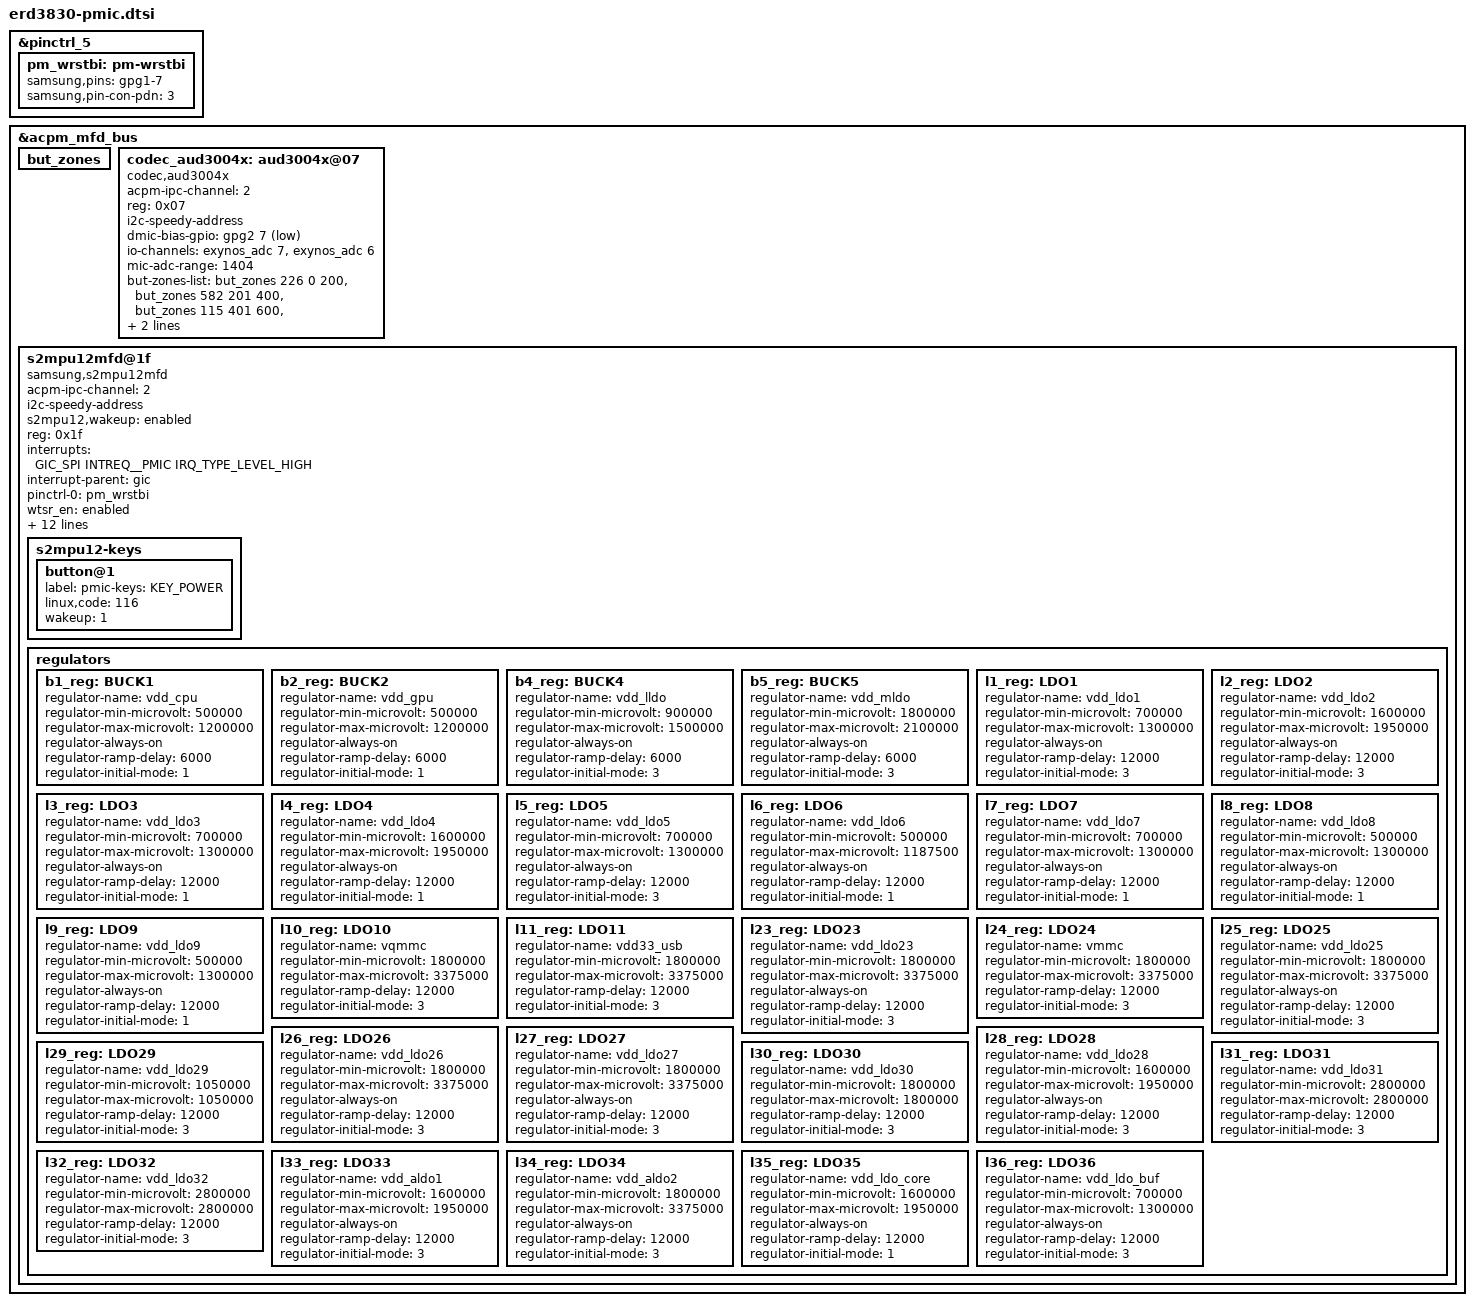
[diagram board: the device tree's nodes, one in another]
/*
 * SAMSUNG S5E3830 AP PMIC device tree source
 *
 * Copyright (c) 2022 Samsung Electronics Co., Ltd.
 *             http://www.samsung.com
 *
 * SAMSUNG S5E3830 AP PMIC device nodes are listed in this file.
 * AP PMIC based board files can include this file and provide
 * values for board specfic bindings.
 *
 * This program is free software; you can redistribute it and/or modify
 * it under the terms of the GNU General Public License version 2 as
 * published by the Free Software Foundation.
 */

&pinctrl_5 {
	pm_wrstbi: pm-wrstbi {
		samsung,pins = "gpg1-7";
		samsung,pin-con-pdn = <3>;
	};
};

&acpm_mfd_bus {
	status = "okay";
	#address-cells = <1>;
	#size-cells = <0>;

	but_zones: but_zones {
		#list-but-cells = <3>;
	};

	codec_aud3004x: aud3004x@07 {
		compatible = "codec,aud3004x";
		acpm-ipc-channel = <2>;
		#sound-dai-cells = <0>;
		reg = <0x07>;
		i2c-speedy-address;
		dmic-bias-gpio = <&gpg2 7 0xf>;
		pinctrl-names = "default";
		io-channels = <&exynos_adc 7>,<&exynos_adc 6>;
		io-channel-names = "adc-gdet","adc-ear";
		#io-channel-cells = <1>;
		mic-adc-range = <1404>;
		but-zones-list = <&but_zones 226 0 200>,
			<&but_zones 582 201 400>,
			<&but_zones 115 401 600>,
			<&but_zones 114 601 1161>;
		btn-release-value = <1404>;
	};

	s2mpu12mfd@1f {
		compatible = "samsung,s2mpu12mfd";
		acpm-ipc-channel = <2>;
		i2c-speedy-address;
		s2mpu12,wakeup = "enabled";
		reg = <0x1f>;
		interrupts = <GIC_SPI INTREQ__PMIC IRQ_TYPE_LEVEL_HIGH>;
		interrupt-parent = <&gic>;
		pinctrl-names = "default";
		pinctrl-0 = <&pm_wrstbi>;
		/* RTC: wtsr/smpl */
		wtsr_en = "enabled"; /* enable */
		smpl_en = "enabled"; /* enable */
		wtsr_timer_val = <3>;	/* 1000ms */
		smpl_timer_val = <4>;	/* 500ms */
		check_jigon = <0>; /* do not check jigon */
		/* RTC: If it's first boot, reset rtc to 1/1/2022 12:00:00(Sat) */
		init_time,sec = <0>;
		init_time,min = <0>;
		init_time,hour = <12>;
		init_time,mday = <1>;
		init_time,mon = <0>;
		init_time,year = <122>;
		init_time,wday = <6>;
		/* Loop BW */
		pmic_loop_bw;

		s2mpu12-keys {
			button@1 {
				label = "pmic-keys: KEY_POWER";
				linux,code = <116>;
				wakeup = <1>;
			};
		};

		regulators {
			b1_reg: BUCK1 {
				regulator-name = "vdd_cpu";
				regulator-min-microvolt = <500000>;
				regulator-max-microvolt = <1200000>;
				regulator-always-on;
				regulator-ramp-delay = <6000>;
				regulator-initial-mode = <1>;
			};

			b2_reg: BUCK2 {
				regulator-name = "vdd_gpu";
				regulator-min-microvolt = <500000>;
				regulator-max-microvolt = <1200000>;
				regulator-always-on;
				regulator-ramp-delay = <6000>;
				regulator-initial-mode = <1>;
			};
/*
			b3_reg: BUCK3 {
				regulator-name = "vdd_cp";
				regulator-min-microvolt = <500000>;
				regulator-max-microvolt = <1200000>;
				regulator-always-on;
				regulator-ramp-delay = <6000>;
				regulator-initial-mode = <3>;
			};
*/
			b4_reg: BUCK4 {
				regulator-name = "vdd_lldo";
				regulator-min-microvolt = <900000>;
				regulator-max-microvolt = <1500000>;
				regulator-always-on;
				regulator-ramp-delay = <6000>;
				regulator-initial-mode = <3>;
			};

			b5_reg: BUCK5 {
				regulator-name = "vdd_mldo";
				regulator-min-microvolt = <1800000>;
				regulator-max-microvolt = <2100000>;
				regulator-always-on;
				regulator-ramp-delay = <6000>;
				regulator-initial-mode = <3>;
			};

			l1_reg: LDO1 {
				regulator-name = "vdd_ldo1";
				regulator-min-microvolt = <700000>;
				regulator-max-microvolt = <1300000>;
				regulator-always-on;
				regulator-ramp-delay = <12000>;
				regulator-initial-mode = <3>;
			};

			l2_reg: LDO2 {
				regulator-name = "vdd_ldo2";
				regulator-min-microvolt = <1600000>;
				regulator-max-microvolt = <1950000>;
				regulator-always-on;
				regulator-ramp-delay = <12000>;
				regulator-initial-mode = <3>;
			};

			l3_reg: LDO3 {
				regulator-name = "vdd_ldo3";
				regulator-min-microvolt = <700000>;
				regulator-max-microvolt = <1300000>;
				regulator-always-on;
				regulator-ramp-delay = <12000>;
				regulator-initial-mode = <1>;
			};

			l4_reg: LDO4 {
				regulator-name = "vdd_ldo4";
				regulator-min-microvolt = <1600000>;
				regulator-max-microvolt = <1950000>;
				regulator-always-on;
				regulator-ramp-delay = <12000>;
				regulator-initial-mode = <1>;
			};

			l5_reg: LDO5 {
				regulator-name = "vdd_ldo5";
				regulator-min-microvolt = <700000>;
				regulator-max-microvolt = <1300000>;
				regulator-always-on;
				regulator-ramp-delay = <12000>;
				regulator-initial-mode = <3>;
			};

			l6_reg: LDO6 {
				regulator-name = "vdd_ldo6";
				regulator-min-microvolt = <500000>;
				regulator-max-microvolt = <1187500>;
				regulator-always-on;
				regulator-ramp-delay = <12000>;
				regulator-initial-mode = <1>;
			};

			l7_reg: LDO7 {
				regulator-name = "vdd_ldo7";
				regulator-min-microvolt = <700000>;
				regulator-max-microvolt = <1300000>;
				regulator-always-on;
				regulator-ramp-delay = <12000>;
				regulator-initial-mode = <1>;
			};

			l8_reg: LDO8 {
				regulator-name = "vdd_ldo8";
				regulator-min-microvolt = <500000>;
				regulator-max-microvolt = <1300000>;
				regulator-always-on;
				regulator-ramp-delay = <12000>;
				regulator-initial-mode = <1>;
			};

			l9_reg: LDO9 {
				regulator-name = "vdd_ldo9";
				regulator-min-microvolt = <500000>;
				regulator-max-microvolt = <1300000>;
				regulator-always-on;
				regulator-ramp-delay = <12000>;
				regulator-initial-mode = <1>;
			};

			l10_reg: LDO10 {
				regulator-name = "vqmmc";
				regulator-min-microvolt = <1800000>;
				regulator-max-microvolt = <3375000>;
				regulator-ramp-delay = <12000>;
				regulator-initial-mode = <3>;
			};

			l11_reg: LDO11 {
				regulator-name = "vdd33_usb";
				regulator-min-microvolt = <1800000>;
				regulator-max-microvolt = <3375000>;
				regulator-ramp-delay = <12000>;
				regulator-initial-mode = <3>;
			};
/*
			l12_reg: LDO12 {
				regulator-name = "vdd_ldo12";
				regulator-min-microvolt = <700000>;
				regulator-max-microvolt = <1300000>;
				regulator-always-on;
				regulator-ramp-delay = <12000>;
				regulator-initial-mode = <3>;
			};

			l13_reg: LDO13 {
				regulator-name = "vdd_ldo13";
				regulator-min-microvolt = <700000>;
				regulator-max-microvolt = <1300000>;
				regulator-always-on;
				regulator-ramp-delay = <12000>;
				regulator-initial-mode = <3>;
			};

			l14_reg: LDO14 {
				regulator-name = "vdd_ldo14";
				regulator-min-microvolt = <1600000>;
				regulator-max-microvolt = <1950000>;
				regulator-always-on;
				regulator-ramp-delay = <12000>;
				regulator-initial-mode = <3>;
			};

			l15_reg: LDO15 {
				regulator-name = "vdd_ldo15";
				regulator-min-microvolt = <1800000>;
				regulator-max-microvolt = <3375000>;
				regulator-always-on;
				regulator-ramp-delay = <12000>;
				regulator-initial-mode = <3>;
			};

			l16_reg: LDO16 {
				regulator-name = "vdd_ldo16";
				regulator-min-microvolt = <1800000>;
				regulator-max-microvolt = <3375000>;
				regulator-always-on;
				regulator-ramp-delay = <12000>;
				regulator-initial-mode = <3>;
			};

			l17_reg: LDO17 {
				regulator-name = "vdd_ldo17";
				regulator-min-microvolt = <700000>;
				regulator-max-microvolt = <1300000>;
				regulator-always-on;
				regulator-ramp-delay = <12000>;
				regulator-initial-mode = <3>;
			};

			l18_reg: LDO18 {
				regulator-name = "vdd_ldo18";
				regulator-min-microvolt = <700000>;
				regulator-max-microvolt = <1300000>;
				regulator-always-on;
				regulator-ramp-delay = <12000>;
				regulator-initial-mode = <3>;
			};

			l19_reg: LDO19 {
				regulator-name = "vdd_ldo19";
				regulator-min-microvolt = <700000>;
				regulator-max-microvolt = <1300000>;
				regulator-always-on;
				regulator-ramp-delay = <12000>;
				regulator-initial-mode = <3>;
			};

			l20_reg: LDO20 {
				regulator-name = "vdd_ldo20";
				regulator-min-microvolt = <1600000>;
				regulator-max-microvolt = <1950000>;
				regulator-always-on;
				regulator-ramp-delay = <12000>;
				regulator-initial-mode = <3>;
			};

			l21_reg: LDO21 {
				regulator-name = "vdd_ldo21";
				regulator-min-microvolt = <1800000>;
				regulator-max-microvolt = <3375000>;
				regulator-always-on;
				regulator-ramp-delay = <12000>;
				regulator-initial-mode = <3>;
			};

			l22_reg: LDO22 {
				regulator-name = "vdd_ldo22";
				regulator-min-microvolt = <1800000>;
				regulator-max-microvolt = <3375000>;
				regulator-always-on;
				regulator-ramp-delay = <12000>;
				regulator-initial-mode = <3>;
			};
*/
			l23_reg: LDO23 {
				regulator-name = "vdd_ldo23";
				regulator-min-microvolt = <1800000>;
				regulator-max-microvolt = <3375000>;
				regulator-always-on;
				regulator-ramp-delay = <12000>;
				regulator-initial-mode = <3>;
			};

			l24_reg: LDO24 {
				regulator-name = "vmmc";
				regulator-min-microvolt = <1800000>;
				regulator-max-microvolt = <3375000>;
				regulator-ramp-delay = <12000>;
				regulator-initial-mode = <3>;
			};

			l25_reg: LDO25 {
				regulator-name = "vdd_ldo25";
				regulator-min-microvolt = <1800000>;
				regulator-max-microvolt = <3375000>;
				regulator-always-on;
				regulator-ramp-delay = <12000>;
				regulator-initial-mode = <3>;
			};

			l26_reg: LDO26 {
				regulator-name = "vdd_ldo26";
				regulator-min-microvolt = <1800000>;
				regulator-max-microvolt = <3375000>;
				regulator-always-on;
				regulator-ramp-delay = <12000>;
				regulator-initial-mode = <3>;
			};

			l27_reg: LDO27 {
				regulator-name = "vdd_ldo27";
				regulator-min-microvolt = <1800000>;
				regulator-max-microvolt = <3375000>;
				regulator-always-on;
				regulator-ramp-delay = <12000>;
				regulator-initial-mode = <3>;
			};

			l28_reg: LDO28 {
				regulator-name = "vdd_ldo28";
				regulator-min-microvolt = <1600000>;
				regulator-max-microvolt = <1950000>;
				//regulator-boot-on;
				regulator-always-on;
				regulator-ramp-delay = <12000>;
				regulator-initial-mode = <3>;
			};

			l29_reg: LDO29 {
				regulator-name = "vdd_ldo29";
				regulator-min-microvolt = <1050000>;
				regulator-max-microvolt = <1050000>;
				regulator-ramp-delay = <12000>;
				regulator-initial-mode = <3>;
			};

			l30_reg: LDO30 {
				regulator-name = "vdd_ldo30";
				regulator-min-microvolt = <1800000>;
				regulator-max-microvolt = <1800000>;
				regulator-ramp-delay = <12000>;
				regulator-initial-mode = <3>;
			};

			l31_reg: LDO31 {
				regulator-name = "vdd_ldo31";
				regulator-min-microvolt = <2800000>;
				regulator-max-microvolt = <2800000>;
				regulator-ramp-delay = <12000>;
				regulator-initial-mode = <3>;
			};

			l32_reg: LDO32 {
				regulator-name = "vdd_ldo32";
				regulator-min-microvolt = <2800000>;
				regulator-max-microvolt = <2800000>;
				regulator-ramp-delay = <12000>;
				regulator-initial-mode = <3>;
			};

			l33_reg: LDO33 {
				regulator-name = "vdd_aldo1";
				regulator-min-microvolt = <1600000>;
				regulator-max-microvolt = <1950000>;
				regulator-always-on;
				regulator-ramp-delay = <12000>;
				regulator-initial-mode = <3>;
			};

			l34_reg: LDO34 {
				regulator-name = "vdd_aldo2";
				regulator-min-microvolt = <1800000>;
				regulator-max-microvolt = <3375000>;
				regulator-always-on;
				regulator-ramp-delay = <12000>;
				regulator-initial-mode = <3>;
			};

			l35_reg: LDO35 {
				regulator-name = "vdd_ldo_core";
				regulator-min-microvolt = <1600000>;
				regulator-max-microvolt = <1950000>;
				regulator-always-on;
				regulator-ramp-delay = <12000>;
				regulator-initial-mode = <1>;
			};

			l36_reg: LDO36 {
				regulator-name = "vdd_ldo_buf";
				regulator-min-microvolt = <700000>;
				regulator-max-microvolt = <1300000>;
				regulator-always-on;
				regulator-ramp-delay = <12000>;
				regulator-initial-mode = <3>;
			};
		}; /* end of regulators */
	}; /* end of s2mpu12mfd@1f */
}; /* end of acpm_mfd_bus */
